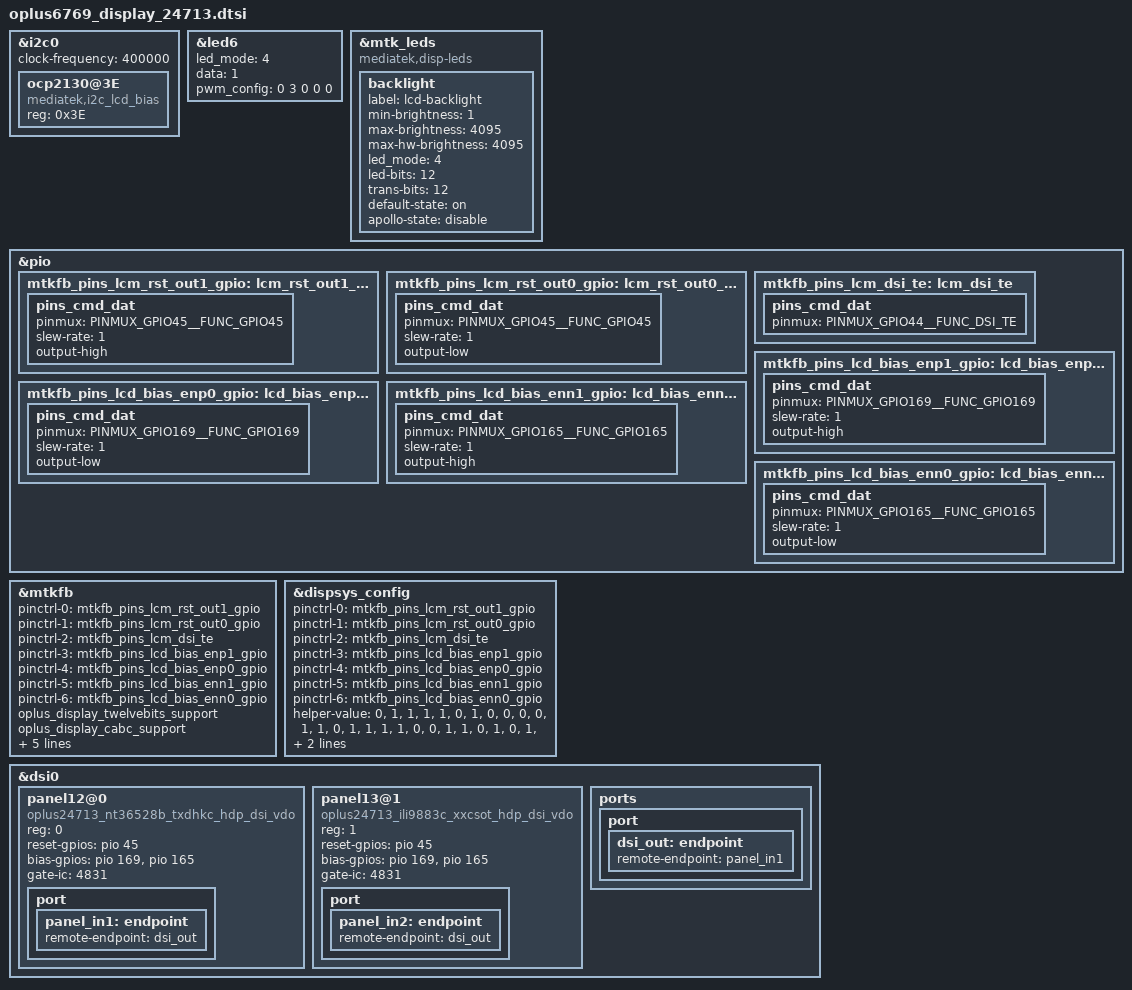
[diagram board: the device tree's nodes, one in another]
// SPDX-License-Identifier: GPL-2.0-only
/*
* Copyright (C) 2020-2021 Oplus. All rights reserved.
*/

/*
 * Add for display bringup
 */

/* lcm_bias:i2c0 */
&i2c0 {
	clock-frequency = <400000>;

	ocp2130@3E {
		compatible = "mediatek,i2c_lcd_bias";
		reg = <0x3E>;
		status = "okay";
	};
};

&led6 {
	led_mode = <4>;
	data = <1>;
	pwm_config = <0 3 0 0 0>;
};
&mtk_leds {
	compatible = "mediatek,disp-leds";

	backlight {
		label = "lcd-backlight";
		min-brightness = <1>;
		max-brightness = <4095>;
		max-hw-brightness = <4095>;
		led_mode = <4>;
		led-bits = <12>;
		trans-bits = <12>;
		default-state = "on";
		apollo-state = "disable";
	};
};

/* DISPSYS GPIO standardization */
&pio {
	mtkfb_pins_lcm_rst_out1_gpio: lcm_rst_out1_gpio {
		pins_cmd_dat {
			pinmux = <PINMUX_GPIO45__FUNC_GPIO45>;
			slew-rate = <1>;
			output-high;
		};
	};

	mtkfb_pins_lcm_rst_out0_gpio: lcm_rst_out0_gpio {
		pins_cmd_dat {
			pinmux = <PINMUX_GPIO45__FUNC_GPIO45>;
			slew-rate = <1>;
			output-low;
		};
	};

	mtkfb_pins_lcm_dsi_te: lcm_dsi_te {
		pins_cmd_dat {
			pinmux = <PINMUX_GPIO44__FUNC_DSI_TE>;
		};
	};

	mtkfb_pins_lcd_bias_enp1_gpio: lcd_bias_enp1_gpio {
		pins_cmd_dat {
			pinmux = <PINMUX_GPIO169__FUNC_GPIO169>;
			slew-rate = <1>;
			output-high;
		};
	};

	mtkfb_pins_lcd_bias_enp0_gpio: lcd_bias_enp0_gpio {
		pins_cmd_dat {
			pinmux = <PINMUX_GPIO169__FUNC_GPIO169>;
			slew-rate = <1>;
			output-low;
		};
	};
	mtkfb_pins_lcd_bias_enn1_gpio: lcd_bias_enn1_gpio {
		pins_cmd_dat {
			pinmux = <PINMUX_GPIO165__FUNC_GPIO165>;
			slew-rate = <1>;
			output-high;
		};
	};

	mtkfb_pins_lcd_bias_enn0_gpio: lcd_bias_enn0_gpio {
		pins_cmd_dat {
			pinmux = <PINMUX_GPIO165__FUNC_GPIO165>;
			slew-rate = <1>;
			output-low;
		};
	};
};

&mtkfb {
	pinctrl-names =
		"lcm_rst_out1_gpio", "lcm_rst_out0_gpio",
		"mode_te_te", "lcd_bias_enp1_gpio",
		"lcd_bias_enp0_gpio",
		"lcd_bias_enn1_gpio",
		"lcd_bias_enn0_gpio";
	pinctrl-0 = <&mtkfb_pins_lcm_rst_out1_gpio>;
	pinctrl-1 = <&mtkfb_pins_lcm_rst_out0_gpio>;
	pinctrl-2 = <&mtkfb_pins_lcm_dsi_te>;
	pinctrl-3 = <&mtkfb_pins_lcd_bias_enp1_gpio>;
	pinctrl-4 = <&mtkfb_pins_lcd_bias_enp0_gpio>;
	pinctrl-5 = <&mtkfb_pins_lcd_bias_enn1_gpio>;
	pinctrl-6 = <&mtkfb_pins_lcd_bias_enn0_gpio>;
	status = "okay";

	oplus_display_twelvebits_support;
	oplus_display_cabc_support;
	oplus_display_panel_cabc_support;
	oplus_display_bls_blmap_support;
	oplus_display_panel_cabc_power_saving_support;
	oplus_display_cabc_cmdq_support;
	oplus_display_normal_max_brightness = <4095>;
};

&dispsys_config {
	pinctrl-names =
		"lcm_rst_out1_gpio", "lcm_rst_out0_gpio",
		"mode_te_te",
        "lcd_bias_enp1_gpio", "lcd_bias_enp0_gpio",
        "lcd_bias_enn1_gpio", "lcd_bias_enn0_gpio";
	pinctrl-0 = <&mtkfb_pins_lcm_rst_out1_gpio>;
	pinctrl-1 = <&mtkfb_pins_lcm_rst_out0_gpio>;
	pinctrl-2 = <&mtkfb_pins_lcm_dsi_te>;
	pinctrl-3 = <&mtkfb_pins_lcd_bias_enp1_gpio>;
	pinctrl-4 = <&mtkfb_pins_lcd_bias_enp0_gpio>;
	pinctrl-5 = <&mtkfb_pins_lcd_bias_enn1_gpio>;
	pinctrl-6 = <&mtkfb_pins_lcd_bias_enn0_gpio>;
	status = "okay";

	helper-value = <0>, /*MTK_DRM_OPT_STAGE*/
		<1>, /*MTK_DRM_OPT_USE_CMDQ*/
		<1>, /*MTK_DRM_OPT_USE_M4U*/
		<1>, /*MTK_DRM_OPT_MMQOS_SUPPORT*/
		<1>, /*MTK_DRM_OPT_MMDVFS_SUPPORT*/
		<0>, /*MTK_DRM_OPT_SODI_SUPPORT*/
		<1>, /*MTK_DRM_OPT_IDLE_MGR*/
		<0>, /*MTK_DRM_OPT_IDLEMGR_SWTCH_DECOUPLE*/
		<0>, /*MTK_DRM_OPT_IDLEMGR_BY_REPAINT*/
		<0>, /*MTK_DRM_OPT_IDLEMGR_ENTER_ULPS*/
		<0>, /*MTK_DRM_OPT_IDLEMGR_KEEP_LP11*/
		<1>, /*MTK_DRM_OPT_DYNAMIC_RDMA_GOLDEN_SETTING*/
		<1>, /*MTK_DRM_OPT_IDLEMGR_DISABLE_ROUTINE_IRQ*/
		<0>, /*MTK_DRM_OPT_MET_LOG*/
		<1>, /*MTK_DRM_OPT_USE_PQ*/
		<1>, /*MTK_DRM_OPT_ESD_CHECK_RECOVERY*/
		<1>, /*MTK_DRM_OPT_ESD_CHECK_SWITCH*/
		<1>, /*MTK_DRM_OPT_PRESENT_FENCE*/
		<0>, /*MTK_DRM_OPT_RDMA_UNDERFLOW_AEE*/
		<0>, /*MTK_DRM_OPT_DSI_UNDERRUN_AEE*/
		<1>, /*MTK_DRM_OPT_HRT*/
		<1>, /*MTK_DRM_OPT_HRT_MODE*/
		<0>, /*MTK_DRM_OPT_DELAYED_TRIGGER*/
		<1>, /*MTK_DRM_OPT_OVL_EXT_LAYER*/
		<0>, /*MTK_DRM_OPT_AOD*/
		<1>, /*MTK_DRM_OPT_RPO*/
		<0>, /*MTK_DRM_OPT_DUAL_PIPE*/
		<0>, /*MTK_DRM_OPT_DC_BY_HRT*/
		<0>, /*MTK_DRM_OPT_OVL_WCG*/
		<0>, /*MTK_DRM_OPT_OVL_SBCH*/
		<1>, /*MTK_DRM_OPT_COMMIT_NO_WAIT_VBLANK*/
		<0>, /*MTK_DRM_OPT_MET*/
		<0>, /*MTK_DRM_OPT_REG_PARSER_RAW_DUMP*/
		<0>, /*MTK_DRM_OPT_VP_PQ*/
		<0>, /*MTK_DRM_OPT_GAME_PQ*/
		<0>, /*MTK_DRM_OPT_MMPATH*/
		<0>, /*MTK_DRM_OPT_HBM*/
		<0>, /*MTK_DRM_OPT_VDS_PATH_SWITCH*/
		<0>, /*MTK_DRM_OPT_LAYER_REC*/
		<1>, /*MTK_DRM_OPT_CLEAR_LAYER*/
		<0>, /*MTK_DRM_OPT_LFR*/
		<0>, /*MTK_DRM_OPT_SF_PF*/
		<1>, /*MTK_DRM_OPT_DYN_MIPI_CHANGE*/
		<0>, /*MTK_DRM_OPT_PRIM_DUAL_PIPE*/
		<0>, /*MTK_DRM_OPT_MSYNC2_0*/
		<0>, /*MTK_DRM_OPT_MML_PRIMARY*/
		<0>, /*MTK_DRM_OPT_DUAL_TE*/
		<0>, /*MTK_DRM_OPT_VIRTUAL_DISP*/
		<0>, /*MTK_DRM_OPT_RES_SWITCH*/
		<0>, /*MTK_DRM_OPT_SHARE_SRAM*/
		<1>; /*MTK_DRM_OPT_SPHRT*/
};

&dsi0 {
	status = "okay";
	#address-cells = <1>;
	#size-cells = <0>;
	panel12@0 {
		compatible = "oplus24713_nt36528b_txdhkc_hdp_dsi_vdo";
		reg = <0>;
		reset-gpios = <&pio 45 0>;
		bias-gpios = <&pio 169 0>,<&pio 165 0>;
		gate-ic = <4831>;
		pinctrl-names = "default";
		port {
			panel_in1: endpoint {
				remote-endpoint = <&dsi_out>;
			};
		};
	};
	panel13@1 {
		compatible = "oplus24713_ili9883c_xxcsot_hdp_dsi_vdo";
		reg = <1>;
		reset-gpios = <&pio 45 0>;
		bias-gpios = <&pio 169 0>,<&pio 165 0>;
		gate-ic = <4831>;
		pinctrl-names = "default";
		port {
			panel_in2: endpoint {
				remote-endpoint = <&dsi_out>;
			};
		};
	};
	ports {
		port {
			dsi_out: endpoint {
				remote-endpoint = <&panel_in1>;
			};
		};
	};
};
/* DISPSYS GPIO standardization end*/
